VERSION " "

NS_ :

BS_:

BU_: AUT REF_ECU

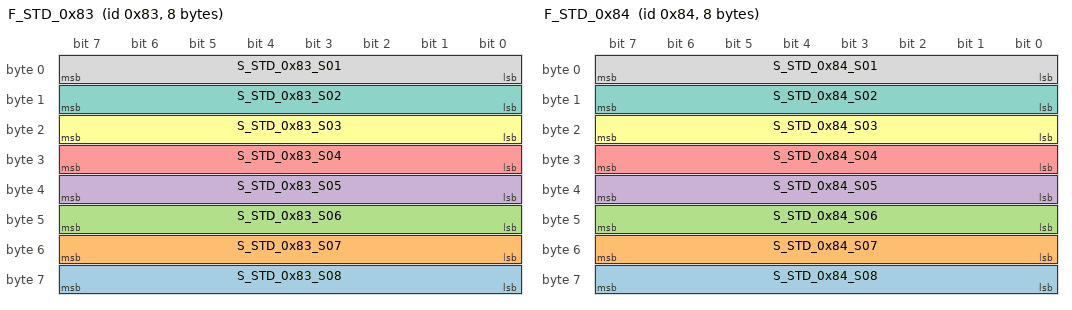
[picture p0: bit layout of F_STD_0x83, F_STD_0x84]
BO_ 131 F_STD_0x83: 8 REF_ECU
 SG_ S_STD_0x83_S08 : 56|8@1+ (1,0) [0|255] ""  AUT
 SG_ S_STD_0x83_S07 : 48|8@1+ (1,0) [0|255] ""  AUT
 SG_ S_STD_0x83_S06 : 40|8@1+ (1,0) [0|255] ""  AUT
 SG_ S_STD_0x83_S05 : 32|8@1+ (1,0) [0|255] ""  AUT
 SG_ S_STD_0x83_S04 : 24|8@1+ (1,0) [0|255] ""  AUT
 SG_ S_STD_0x83_S03 : 16|8@1+ (1,0) [0|255] ""  AUT
 SG_ S_STD_0x83_S02 : 8|8@1+ (1,0) [0|255] ""  AUT
 SG_ S_STD_0x83_S01 : 0|8@1+ (1,0) [0|255] ""  AUT

BO_ 132 F_STD_0x84: 8 REF_ECU
 SG_ S_STD_0x84_S08 : 56|8@1+ (1,0) [0|255] ""  AUT
 SG_ S_STD_0x84_S07 : 48|8@1+ (1,0) [0|255] ""  AUT
 SG_ S_STD_0x84_S06 : 40|8@1+ (1,0) [0|255] ""  AUT
 SG_ S_STD_0x84_S05 : 32|8@1+ (1,0) [0|255] ""  AUT
 SG_ S_STD_0x84_S04 : 24|8@1+ (1,0) [0|255] ""  AUT
 SG_ S_STD_0x84_S03 : 16|8@1+ (1,0) [0|255] ""  AUT
 SG_ S_STD_0x84_S02 : 8|8@1+ (1,0) [0|255] ""  AUT
 SG_ S_STD_0x84_S01 : 0|8@1+ (1,0) [0|255] ""  AUT

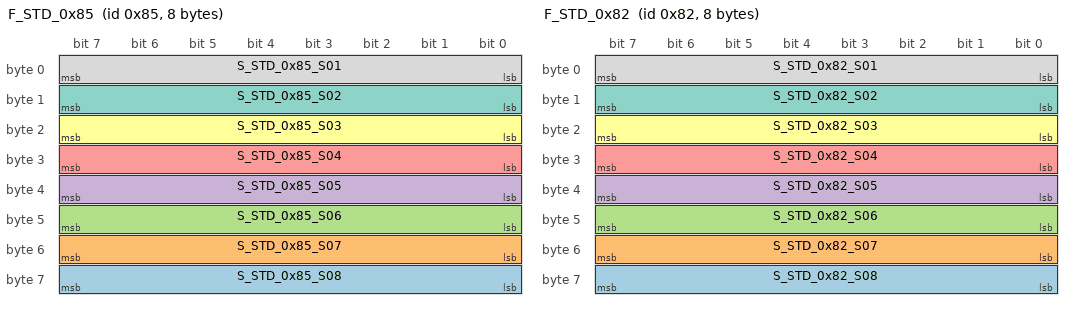
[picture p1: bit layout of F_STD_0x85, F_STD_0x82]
BO_ 133 F_STD_0x85: 8 REF_ECU
 SG_ S_STD_0x85_S08 : 56|8@1+ (1,0) [0|255] ""  AUT
 SG_ S_STD_0x85_S07 : 48|8@1+ (1,0) [0|255] ""  AUT
 SG_ S_STD_0x85_S06 : 40|8@1+ (1,0) [0|255] ""  AUT
 SG_ S_STD_0x85_S05 : 32|8@1+ (1,0) [0|255] ""  AUT
 SG_ S_STD_0x85_S04 : 24|8@1+ (1,0) [0|255] ""  AUT
 SG_ S_STD_0x85_S03 : 16|8@1+ (1,0) [0|255] ""  AUT
 SG_ S_STD_0x85_S02 : 8|8@1+ (1,0) [0|255] ""  AUT
 SG_ S_STD_0x85_S01 : 0|8@1+ (1,0) [0|255] ""  AUT

BO_ 130 F_STD_0x82: 8 REF_ECU
 SG_ S_STD_0x82_S08 : 56|8@1+ (1,0) [0|255] ""  AUT
 SG_ S_STD_0x82_S07 : 48|8@1+ (1,0) [0|255] ""  AUT
 SG_ S_STD_0x82_S06 : 40|8@1+ (1,0) [0|255] ""  AUT
 SG_ S_STD_0x82_S05 : 32|8@1+ (1,0) [0|255] ""  AUT
 SG_ S_STD_0x82_S04 : 24|8@1+ (1,0) [0|255] ""  AUT
 SG_ S_STD_0x82_S03 : 16|8@1+ (1,0) [0|255] ""  AUT
 SG_ S_STD_0x82_S02 : 8|8@1+ (1,0) [0|255] ""  AUT
 SG_ S_STD_0x82_S01 : 0|8@1+ (1,0) [0|255] ""  AUT

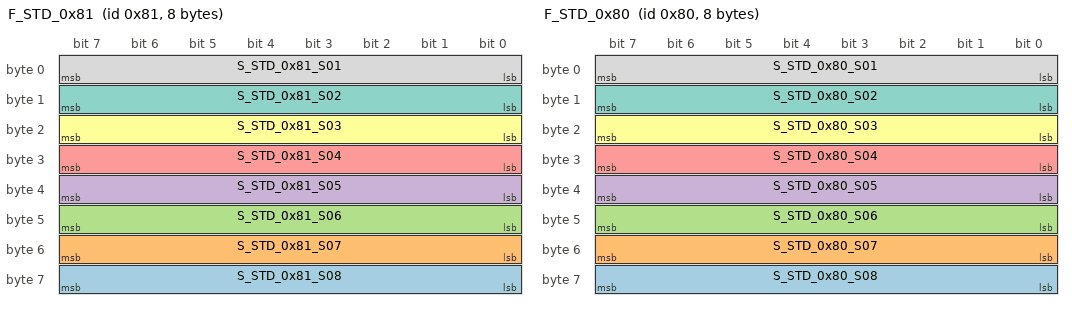
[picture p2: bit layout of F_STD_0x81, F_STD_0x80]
BO_ 129 F_STD_0x81: 8 REF_ECU
 SG_ S_STD_0x81_S08 : 56|8@1+ (1,0) [0|255] ""  AUT
 SG_ S_STD_0x81_S07 : 48|8@1+ (1,0) [0|255] ""  AUT
 SG_ S_STD_0x81_S06 : 40|8@1+ (1,0) [0|255] ""  AUT
 SG_ S_STD_0x81_S05 : 32|8@1+ (1,0) [0|255] ""  AUT
 SG_ S_STD_0x81_S04 : 24|8@1+ (1,0) [0|255] ""  AUT
 SG_ S_STD_0x81_S03 : 16|8@1+ (1,0) [0|255] ""  AUT
 SG_ S_STD_0x81_S02 : 8|8@1+ (1,0) [0|255] ""  AUT
 SG_ S_STD_0x81_S01 : 0|8@1+ (1,0) [0|255] ""  AUT

BO_ 128 F_STD_0x80: 8 REF_ECU
 SG_ S_STD_0x80_S08 : 56|8@1+ (1,0) [0|255] ""  AUT
 SG_ S_STD_0x80_S07 : 48|8@1+ (1,0) [0|255] ""  AUT
 SG_ S_STD_0x80_S06 : 40|8@1+ (1,0) [0|255] ""  AUT
 SG_ S_STD_0x80_S05 : 32|8@1+ (1,0) [0|255] ""  AUT
 SG_ S_STD_0x80_S04 : 24|8@1+ (1,0) [0|255] ""  AUT
 SG_ S_STD_0x80_S03 : 16|8@1+ (1,0) [0|255] ""  AUT
 SG_ S_STD_0x80_S02 : 8|8@1+ (1,0) [0|255] ""  AUT
 SG_ S_STD_0x80_S01 : 0|8@1+ (1,0) [0|255] ""  AUT

BA_DEF_  "BusType" STRING ;
BA_DEF_DEF_  "BusType" "";
BA_ "BusType" "CAN";
